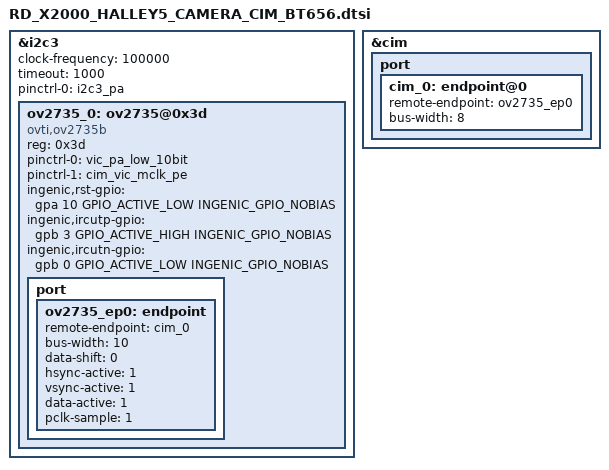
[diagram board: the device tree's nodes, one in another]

&i2c3 {
	status = "okay";
	clock-frequency = <100000>;
	timeout = <1000>;
	pinctrl-names = "default";
	pinctrl-0 = <&i2c3_pa>;

	/*RD_X2000_HALLEY5_CAMERA_V4.2 DVP interface*/
	ov2735_0:ov2735@0x3d {
		status = "ok";
		compatible = "ovti,ov2735b";
		reg = <0x3d>;
		pinctrl-names = "default", "default";
		pinctrl-0 = <&vic_pa_low_10bit>;
		pinctrl-1 = <&cim_vic_mclk_pe>;

		ingenic,rst-gpio = <&gpa 10 GPIO_ACTIVE_LOW INGENIC_GPIO_NOBIAS>;
		ingenic,ircutp-gpio = <&gpb 3 GPIO_ACTIVE_HIGH INGENIC_GPIO_NOBIAS>;
		ingenic,ircutn-gpio = <&gpb 0 GPIO_ACTIVE_LOW INGENIC_GPIO_NOBIAS>;

		port {
			ov2735_ep0:endpoint {
				remote-endpoint = <&cim_0>;
				bus-width = <10>;	/* Used data lines */
				data-shift = <0>;	/* Lines 9:0 are used */

				/* If hsync-active/vsync-active are missing,
				   embedded BT.656 sync is used */
				hsync-active = <1>;	/* Active high */
				vsync-active = <1>;	/* Active high */
				data-active = <1>;	/* Active high */
				pclk-sample = <1>;	/* Rising */
			};
		};
	};

};

&cim {
	status = "okay";
	port {
		cim_0: endpoint@0 {
			remote-endpoint = <&ov2735_ep0>;
			bus-width = <8>;
		};
	};
};




